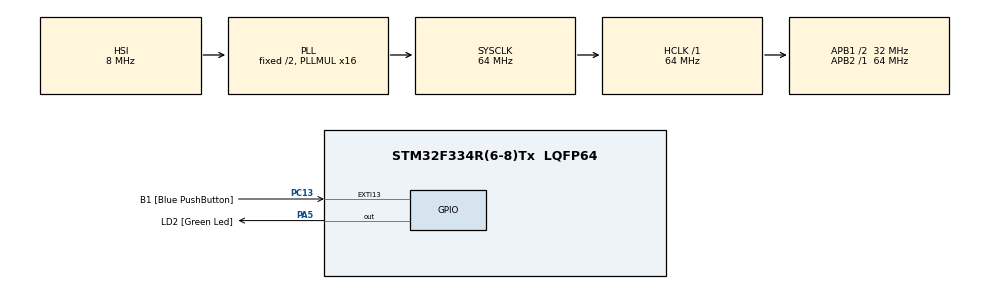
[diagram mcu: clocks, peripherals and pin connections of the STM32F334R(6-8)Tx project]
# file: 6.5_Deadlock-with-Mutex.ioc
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Mcu.Family=STM32F3
Mcu.Name=STM32F334R(6-8)Tx
Mcu.Package=LQFP64
NVIC.PriorityGroup=NVIC_PRIORITYGROUP_4
NVIC.TIM6_DAC1_IRQn=true\:0\:0\:false\:false\:true\:false\:true\:true
NVIC.TimeBase=TIM6_DAC1_IRQn
NVIC.TimeBaseIP=TIM6
PA13.GPIO_Label=TMS
PA13.Signal=SYS_JTMS-SWDIO
PA14.GPIO_Label=TCK
PA14.Signal=SYS_JTCK-SWCLK
PA2.GPIO_Label=USART_TX
PA2.Signal=USART2_TX
PA3.GPIO_Label=USART_RX
PA3.Signal=USART2_RX
PA5.GPIO_Label=LD2 [Green Led]
PA5.Signal=GPIO_Output
PB3.GPIO_Label=SWO
PB3.Signal=SYS_JTDO-TRACESWO
PC13.GPIO_Label=B1 [Blue PushButton]
PC13.GPIO_ModeDefaultEXTI=GPIO_MODE_IT_FALLING
PC13.Signal=GPXTI13
PC14\ /\ OSC32_IN.Signal=RCC_OSC32_IN
PC15\ /\ OSC32_OUT.GPIO_Label=RCC_OSC32_OUT
PC15\ /\ OSC32_OUT.Signal=RCC_OSC32_OUT
PF0\ /\ OSC_IN.Signal=RCC_OSC_IN
PF1\ /\ OSC_OUT.Signal=RCC_OSC_OUT
ProjectManager.HeapSize=0x200
ProjectManager.StackSize=0x400
ProjectManager.TargetToolchain=STM32CubeIDE
RCC.AHBFreq_Value=64000000
RCC.APB1CLKDivider=RCC_HCLK_DIV2
RCC.APB1Freq_Value=32000000
RCC.APB1TimFreq_Value=64000000
RCC.APB2Freq_Value=64000000
RCC.APB2TimFreq_Value=64000000
RCC.CortexFreq_Value=64000000
RCC.FLatency-AdvancedSettings=FLASH_LATENCY_2
RCC.HCLKFreq_Value=64000000
RCC.HSE_VALUE=8000000
RCC.HSI_VALUE=8000000
RCC.LSE_VALUE=32768
RCC.PLLMUL=RCC_PLL_MUL16
RCC.SYSCLKFreq_VALUE=64000000
RCC.SYSCLKSourceVirtual=RCC_SYSCLKSOURCE_PLLCLK
VP_SYS_VS_tim6.Mode=TIM6
board=NUCLEO-F334R8

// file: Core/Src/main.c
/* USER CODE BEGIN Header */
/**
  ******************************************************************************
  * @file           : main.c
  * @brief          : Main program body
  ******************************************************************************
here we have created a Task1 which aquires xMutex and task2 is created within Tsk1 having a Higher priority
  *
  ******************************************************************************
  */
/* USER CODE END Header */
#include "main.h"

/* USER CODE BEGIN Includes */
#include"FreeRTOS.h"
#include"task.h"
#include"semphr.h"
#include"stdio.h"
/* USER CODE END Includes */

/* USER CODE BEGIN PV */
SemaphoreHandle_t xMutex;
SemaphoreHandle_t yMutex;
/* USER CODE END PV */

void SystemClock_Config(void);
static void MX_GPIO_Init(void);
/* USER CODE BEGIN PFP */
void Task1(void *p);
void Task2(void *p);
/* USER CODE END PFP */

int main(void)
{

  /* MCU Configuration--------------------------------------------------------*/

  /* Reset of all peripherals, Initializes the Flash interface and the Systick. */
  HAL_Init();

  /* Configure the system clock */
  SystemClock_Config();

  /* Initialize all configured peripherals */
  MX_GPIO_Init();
  /* USER CODE BEGIN 2 */

  xMutex = xSemaphoreCreateMutex(); // create mutex with name xMutex
  yMutex = xSemaphoreCreateMutex(); //  create mutex with name yMutex

  xTaskCreate(Task1, "Task1",100,NULL,1,NULL); // Create Task1 with priority 1

  vTaskStartScheduler();
  xSemaphoreGive(xMutex); // make available xMutex
  xSemaphoreGive(yMutex);  // make available yMutex

  vTaskStartScheduler();

  /* USER CODE END 2 */

  /* Infinite loop */
  while (1)
  {

  }
}

void SystemClock_Config(void)
{
  RCC_OscInitTypeDef RCC_OscInitStruct = {0};
  RCC_ClkInitTypeDef RCC_ClkInitStruct = {0};

  /** Initializes the RCC Oscillators according to the specified parameters
  * in the RCC_OscInitTypeDef structure.
  */
  RCC_OscInitStruct.OscillatorType = RCC_OSCILLATORTYPE_HSI;
  RCC_OscInitStruct.HSIState = RCC_HSI_ON;
  RCC_OscInitStruct.HSICalibrationValue = RCC_HSICALIBRATION_DEFAULT;
  RCC_OscInitStruct.PLL.PLLState = RCC_PLL_ON;
  RCC_OscInitStruct.PLL.PLLSource = RCC_PLLSOURCE_HSI;
  RCC_OscInitStruct.PLL.PLLMUL = RCC_PLL_MUL16;
  if (HAL_RCC_OscConfig(&RCC_OscInitStruct) != HAL_OK)
  {
    Error_Handler();
  }

  /** Initializes the CPU, AHB and APB buses clocks
  */
  RCC_ClkInitStruct.ClockType = RCC_CLOCKTYPE_HCLK|RCC_CLOCKTYPE_SYSCLK
                              |RCC_CLOCKTYPE_PCLK1|RCC_CLOCKTYPE_PCLK2;
  RCC_ClkInitStruct.SYSCLKSource = RCC_SYSCLKSOURCE_PLLCLK;
  RCC_ClkInitStruct.AHBCLKDivider = RCC_SYSCLK_DIV1;
  RCC_ClkInitStruct.APB1CLKDivider = RCC_HCLK_DIV2;
  RCC_ClkInitStruct.APB2CLKDivider = RCC_HCLK_DIV1;

  if (HAL_RCC_ClockConfig(&RCC_ClkInitStruct, FLASH_LATENCY_2) != HAL_OK)
  {
    Error_Handler();
  }
}

static void MX_GPIO_Init(void)
{
  GPIO_InitTypeDef GPIO_InitStruct = {0};

  /* GPIO Ports Clock Enable */
  __HAL_RCC_GPIOC_CLK_ENABLE();
  __HAL_RCC_GPIOF_CLK_ENABLE();
  __HAL_RCC_GPIOA_CLK_ENABLE();
  __HAL_RCC_GPIOB_CLK_ENABLE();

  /*Configure GPIO pin Output Level */
  HAL_GPIO_WritePin(LD2_GPIO_Port, LD2_Pin, GPIO_PIN_RESET);

  /*Configure GPIO pin : B1_Pin */
  GPIO_InitStruct.Pin = B1_Pin;
  GPIO_InitStruct.Mode = GPIO_MODE_IT_FALLING;
  GPIO_InitStruct.Pull = GPIO_NOPULL;
  HAL_GPIO_Init(B1_GPIO_Port, &GPIO_InitStruct);

  /*Configure GPIO pins : USART_TX_Pin USART_RX_Pin */
  GPIO_InitStruct.Pin = USART_TX_Pin|USART_RX_Pin;
  GPIO_InitStruct.Mode = GPIO_MODE_AF_PP;
  GPIO_InitStruct.Pull = GPIO_NOPULL;
  GPIO_InitStruct.Speed = GPIO_SPEED_FREQ_HIGH;
  GPIO_InitStruct.Alternate = GPIO_AF7_USART2;
  HAL_GPIO_Init(GPIOA, &GPIO_InitStruct);

  /*Configure GPIO pin : LD2_Pin */
  GPIO_InitStruct.Pin = LD2_Pin;
  GPIO_InitStruct.Mode = GPIO_MODE_OUTPUT_PP;
  GPIO_InitStruct.Pull = GPIO_NOPULL;
  GPIO_InitStruct.Speed = GPIO_SPEED_FREQ_LOW;
  HAL_GPIO_Init(LD2_GPIO_Port, &GPIO_InitStruct);

}

/* USER CODE BEGIN 4 */

void Task1(void *p)
{
  while(1)
  {
   xSemaphoreTake(xMutex,portMAX_DELAY);
   printf("Inside Task1\n");
   xTaskCreate(Task2, "Task2", 100,NULL,2,NULL);
   printf("Task1 attempting to take yMutex\n");
   xSemaphoreTake(yMutex,portMAX_DELAY);
   xSemaphoreGive(xMutex);
   vTaskDelay(1);
  }
}

void Task2(void *p)
{
  while(1)
  {
    xSemaphoreTake(yMutex,portMAX_DELAY);
    printf("Inside Task2\n");
    printf("Task2 attempting to take xMutex\n");
    xSemaphoreTake(xMutex,portMAX_DELAY);
    xSemaphoreGive(yMutex);
    vTaskDelay(1);
  }
}

/* USER CODE END 4 */

void HAL_TIM_PeriodElapsedCallback(TIM_HandleTypeDef *htim)
{
  if (htim->Instance == TIM6) {
    HAL_IncTick();
  }
}

void Error_Handler(void)
{
  __disable_irq();
  while (1)
  {
  }
}
